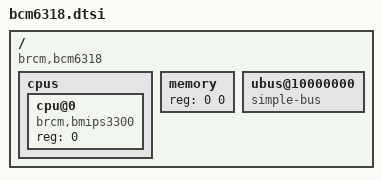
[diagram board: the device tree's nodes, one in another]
/ {
	#address-cells = <1>;
	#size-cells = <1>;
	compatible = "brcm,bcm6318";

	cpus {
		#address-cells = <1>;
		#size-cells = <0>;

		cpu@0 {
			compatible = "brcm,bmips3300", "mips,mips4Kc";
			device_type = "cpu";
			reg = <0>;
		};
	};

	memory { device_type = "memory"; reg = <0 0>; };

	ubus@10000000 {
		#address-cells = <1>;
		#size-cells = <1>;
		ranges;
		compatible = "simple-bus";
	};
};
